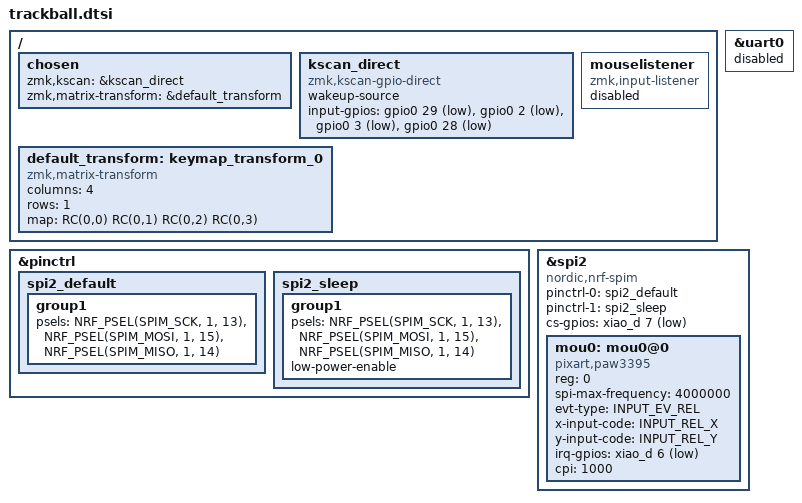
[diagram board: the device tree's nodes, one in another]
/*
 * Copyright (c) 2022 The ZMK Contributors
 *
 * SPDX-License-Identifier: MIT
 */
#include <dt-bindings/zmk/matrix_transform.h>

/ {
	chosen {
		zmk,kscan = &kscan_direct;
		zmk,matrix-transform = &default_transform;
	};
    kscan_direct: kscan_direct {
        compatible = "zmk,kscan-gpio-direct";
        wakeup-source;

        input-gpios
        = <&gpio0 29 (GPIO_ACTIVE_LOW | GPIO_PULL_UP)>
        , <&gpio0 2 (GPIO_ACTIVE_LOW | GPIO_PULL_UP)>
        , <&gpio0 3 (GPIO_ACTIVE_LOW | GPIO_PULL_UP)>
        , <&gpio0 28 (GPIO_ACTIVE_LOW | GPIO_PULL_UP)>;

    };

    default_transform: keymap_transform_0 {
        compatible = "zmk,matrix-transform";
        columns = <4>;
        rows = <1>;
        map = < RC(0,0) RC(0,1) RC(0,2) RC(0,3) >;
    };

};

&uart0 {
	status = "disabled";
};


&pinctrl {
    /* configuration for spi2 device, default state */
    spi2_default: spi2_default {
        group1 {
            psels = <NRF_PSEL(SPIM_SCK, 1, 13)>,
                    <NRF_PSEL(SPIM_MOSI, 1, 15)>,
                    <NRF_PSEL(SPIM_MISO, 1, 14)>;
        };
    };
    /* configuration for spi2 device, sleep state */
    spi2_sleep: spi2_sleep {
        group1 {
            psels = <NRF_PSEL(SPIM_SCK, 1, 13)>,
                    <NRF_PSEL(SPIM_MOSI, 1, 15)>,
                    <NRF_PSEL(SPIM_MISO, 1, 14)>;
            low-power-enable;
        };
    };
};

&spi2 {
    compatible = "nordic,nrf-spim";
    status = "okay";
    pinctrl-0 = <&spi2_default>;
    pinctrl-1 = <&spi2_sleep>;
    pinctrl-names = "default", "sleep";
};

// devices on spi2

// CS pins for devices on spi2
&spi2 {
    cs-gpios = <&xiao_d 7 GPIO_ACTIVE_LOW>;
};

#include <zephyr/dt-bindings/input/input-event-codes.h>

&spi2 {
    mou0: mou0@0 {
        status = "okay";
        compatible = "pixart,paw3395";
        reg = <0>;
        spi-max-frequency = <4000000>;
        evt-type = <INPUT_EV_REL>;
        x-input-code = <INPUT_REL_X>;
        y-input-code = <INPUT_REL_Y>;
        irq-gpios = <&xiao_d 6 (GPIO_ACTIVE_LOW | GPIO_PULL_UP)>;
        cpi = <1000>;
    };
};

/ {
    mouselistener: mouselistener {
        compatible = "zmk,input-listener";
        status = "disabled";
    };
};
